VERSION ""

NS_ :

BS_:

BU_: vcu bms inverter

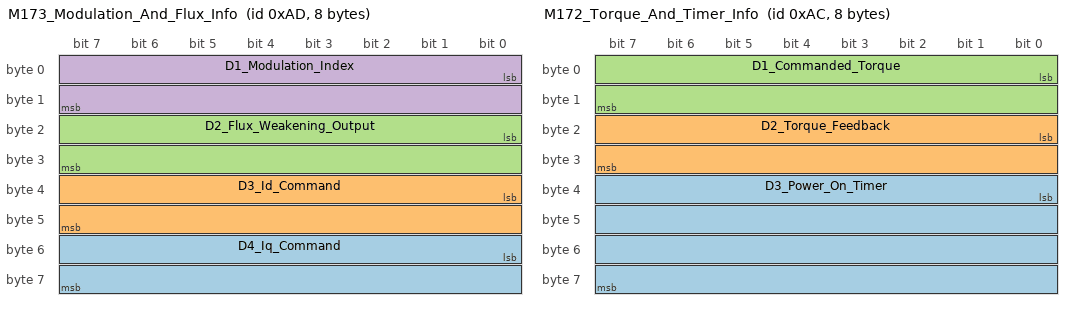
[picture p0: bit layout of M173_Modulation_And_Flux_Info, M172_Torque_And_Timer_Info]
BO_ 173 M173_Modulation_And_Flux_Info: 8 RMS_PM_Controller
 SG_ D4_Iq_Command : 48|16@1- (0.1,0) [-3276.8|3276.7] "" Vector__XXX
 SG_ D3_Id_Command : 32|16@1- (0.1,0) [-3276.8|3276.7] "" Vector__XXX
 SG_ D2_Flux_Weakening_Output : 16|16@1- (0.1,0) [-3276.8|3276.7] "" Vector__XXX
 SG_ D1_Modulation_Index : 0|16@1- (0.0001,0) [-3.2768|3.2767] "" Vector__XXX

BO_ 172 M172_Torque_And_Timer_Info: 8 RMS_PM_Controller
 SG_ D3_Power_On_Timer : 32|32@1+ (0.003,0) [0|12884800.0] "" Vector__XXX
 SG_ D2_Torque_Feedback : 16|16@1- (0.1,0) [-3276.8|3276.7] "" Vector__XXX
 SG_ D1_Commanded_Torque : 0|16@1- (0.1,0) [-3276.8|3276.7] "" Vector__XXX

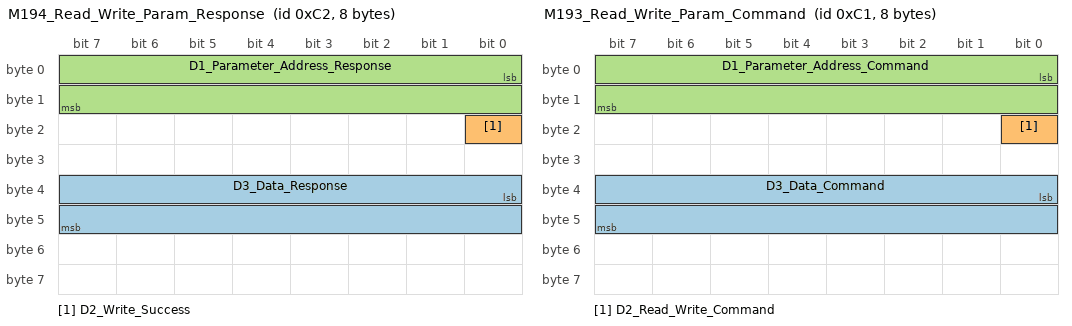
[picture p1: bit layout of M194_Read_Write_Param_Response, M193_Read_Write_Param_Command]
BO_ 194 M194_Read_Write_Param_Response: 8 RMS_PM_Controller
 SG_ D3_Data_Response : 32|16@1- (1,0) [-32768|32767] "" Vector__XXX
 SG_ D2_Write_Success : 16|1@1+ (1,0) [0|1] "" Vector__XXX
 SG_ D1_Parameter_Address_Response : 0|16@1+ (1,0) [0|65535] "" Vector__XXX

BO_ 193 M193_Read_Write_Param_Command: 8 Vector__XXX
 SG_ D3_Data_Command : 32|16@1- (1,0) [-32768|32767] "" Vector__XXX
 SG_ D2_Read_Write_Command : 16|1@1+ (1,0) [0|1] "" Vector__XXX
 SG_ D1_Parameter_Address_Command : 0|16@1+ (1,0) [0|65535] "" Vector__XXX

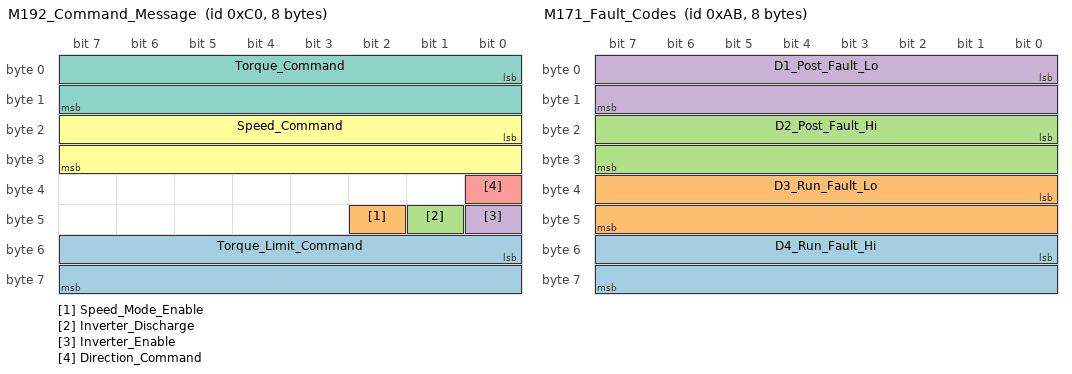
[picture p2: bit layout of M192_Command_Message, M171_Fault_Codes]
BO_ 192 M192_Command_Message: 8 Vector__XXX
 SG_ Torque_Limit_Command : 48|16@1- (0.1,0) [-3276.8|3276.7] "" Vector__XXX
 SG_ Speed_Mode_Enable : 42|1@1+ (1,0) [0|1] "" Vector__XXX
 SG_ Inverter_Discharge : 41|1@1+ (1,0) [0|1] "" Vector__XXX
 SG_ Inverter_Enable : 40|1@1+ (1,0) [0|1] "" Vector__XXX
 SG_ Direction_Command : 32|1@1+ (1,0) [0|1] "" Vector__XXX
 SG_ Speed_Command : 16|16@1- (1,0) [-32768|32767] "" Vector__XXX
 SG_ Torque_Command : 0|16@1- (0.1,0) [-3276.8|3276.7] "" Vector__XXX

BO_ 171 M171_Fault_Codes: 8 RMS_PM_Controller
 SG_ D4_Run_Fault_Hi : 48|16@1+ (1,0) [0|65535] "" Vector__XXX
 SG_ D3_Run_Fault_Lo : 32|16@1+ (1,0) [0|65535] "" Vector__XXX
 SG_ D2_Post_Fault_Hi : 16|16@1+ (1,0) [0|65535] "" Vector__XXX
 SG_ D1_Post_Fault_Lo : 0|16@1+ (1,0) [0|65535] "" Vector__XXX

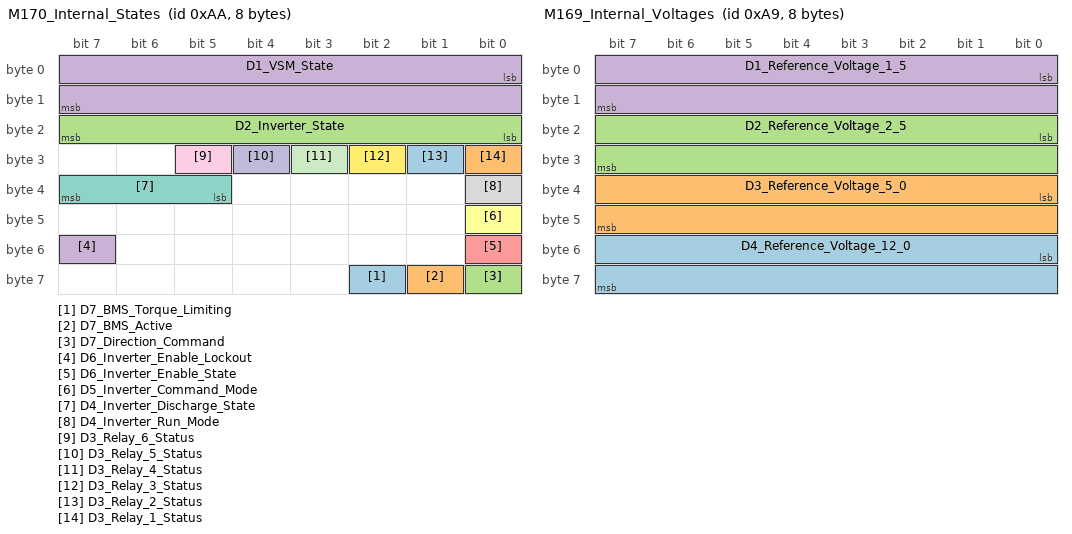
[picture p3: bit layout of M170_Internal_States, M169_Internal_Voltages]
BO_ 170 M170_Internal_States: 8 RMS_PM_Controller
 SG_ D7_BMS_Torque_Limiting : 58|1@1+ (1,0) [0|0] "" Vector__XXX
 SG_ D7_BMS_Active : 57|1@1+ (1,0) [0|1] "" Vector__XXX
 SG_ D7_Direction_Command : 56|1@1+ (1,0) [0|1] "" Vector__XXX
 SG_ D6_Inverter_Enable_Lockout : 55|1@1+ (1,0) [0|1] "" Vector__XXX
 SG_ D6_Inverter_Enable_State : 48|1@1+ (1,0) [0|1] "" Vector__XXX
 SG_ D5_Inverter_Command_Mode : 40|1@1+ (1,0) [0|1] "" Vector__XXX
 SG_ D4_Inverter_Discharge_State : 37|3@1+ (1,0) [0|7] "" Vector__XXX
 SG_ D4_Inverter_Run_Mode : 32|1@1+ (1,0) [0|1] "" Vector__XXX
 SG_ D3_Relay_6_Status : 29|1@1+ (1,0) [0|1] "" Vector__XXX
 SG_ D3_Relay_5_Status : 28|1@1+ (1,0) [0|1] "" Vector__XXX
 SG_ D3_Relay_4_Status : 27|1@1+ (1,0) [0|1] "" Vector__XXX
 SG_ D3_Relay_3_Status : 26|1@1+ (1,0) [0|1] "" Vector__XXX
 SG_ D3_Relay_2_Status : 25|1@1+ (1,0) [0|1] "" Vector__XXX
 SG_ D3_Relay_1_Status : 24|1@1+ (1,0) [0|1] "" Vector__XXX
 SG_ D2_Inverter_State : 16|8@1+ (1,0) [0|255] "" Vector__XXX
 SG_ D1_VSM_State : 0|16@1+ (1,0) [0|15] "" Vector__XXX

BO_ 169 M169_Internal_Voltages: 8 RMS_PM_Controller
 SG_ D4_Reference_Voltage_12_0 : 48|16@1- (0.01,0) [-327.68|327.67] "" Vector__XXX
 SG_ D3_Reference_Voltage_5_0 : 32|16@1- (0.01,0) [-327.68|327.67] "" Vector__XXX
 SG_ D2_Reference_Voltage_2_5 : 16|16@1- (0.01,0) [-327.68|327.67] "" Vector__XXX
 SG_ D1_Reference_Voltage_1_5 : 0|16@1- (0.01,0) [-327.68|327.67] "" Vector__XXX

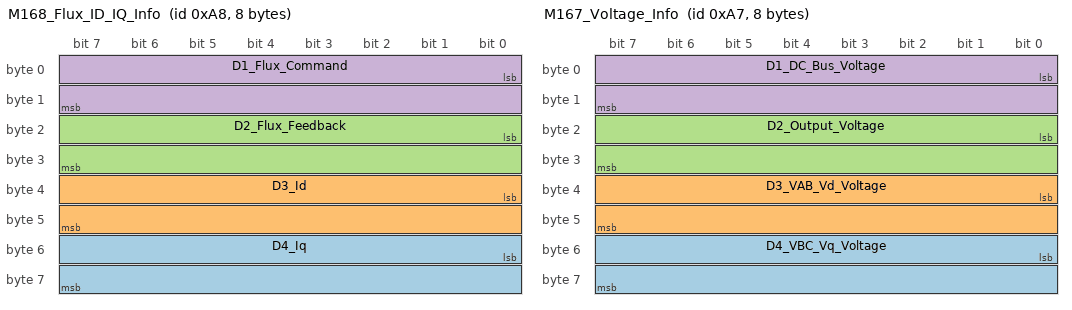
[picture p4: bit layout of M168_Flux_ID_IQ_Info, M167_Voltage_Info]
BO_ 168 M168_Flux_ID_IQ_Info: 8 RMS_PM_Controller
 SG_ D4_Iq : 48|16@1- (0.1,0) [-3276.8|3276.7] "" Vector__XXX
 SG_ D3_Id : 32|16@1- (0.1,0) [-3276.8|3276.7] "" Vector__XXX
 SG_ D2_Flux_Feedback : 16|16@1- (0.001,0) [-32.768|32.767] "" Vector__XXX
 SG_ D1_Flux_Command : 0|16@1- (0.001,0) [-32.768|32.767] "" Vector__XXX

BO_ 167 M167_Voltage_Info: 8 RMS_PM_Controller
 SG_ D4_VBC_Vq_Voltage : 48|16@1- (0.1,0) [-3276.8|3276.7] "" Vector__XXX
 SG_ D3_VAB_Vd_Voltage : 32|16@1- (0.1,0) [-3276.8|3276.7] "" Vector__XXX
 SG_ D2_Output_Voltage : 16|16@1- (0.1,0) [-3276.8|3276.7] "" Vector__XXX
 SG_ D1_DC_Bus_Voltage : 0|16@1- (0.1,0) [-3276.8|3276.7] "" Vector__XXX

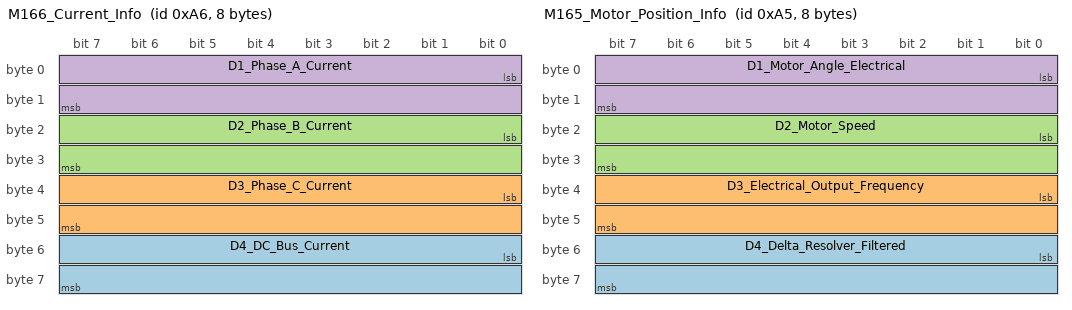
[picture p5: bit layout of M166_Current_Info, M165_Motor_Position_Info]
BO_ 166 M166_Current_Info: 8 RMS_PM_Controller
 SG_ D4_DC_Bus_Current : 48|16@1- (0.1,0) [-3276.8|3276.7] "" Vector__XXX
 SG_ D3_Phase_C_Current : 32|16@1- (0.1,0) [-3276.8|3276.7] "" Vector__XXX
 SG_ D2_Phase_B_Current : 16|16@1- (0.1,0) [-3276.8|3276.7] "" Vector__XXX
 SG_ D1_Phase_A_Current : 0|16@1- (0.1,0) [-3276.8|3276.7] "" Vector__XXX

BO_ 165 M165_Motor_Position_Info: 8 RMS_PM_Controller
 SG_ D4_Delta_Resolver_Filtered : 48|16@1- (0.1,0) [-3276.8|3276.7] "" Vector__XXX
 SG_ D3_Electrical_Output_Frequency : 32|16@1- (0.1,0) [-3276.8|3276.7] "" Vector__XXX
 SG_ D2_Motor_Speed : 16|16@1- (1,0) [-32768|32767] "" Vector__XXX
 SG_ D1_Motor_Angle_Electrical : 0|16@1+ (0.1,0) [0|6553.5] "" Vector__XXX

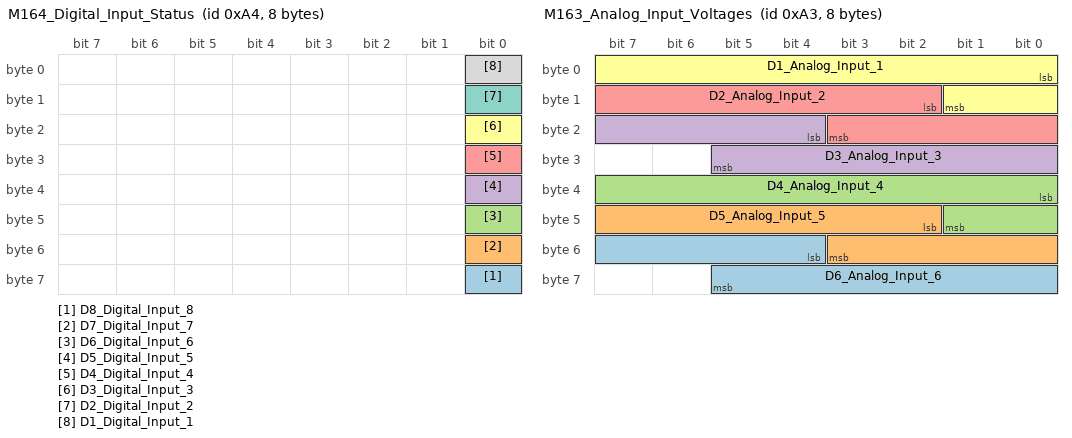
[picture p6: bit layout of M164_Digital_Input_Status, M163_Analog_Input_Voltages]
BO_ 164 M164_Digital_Input_Status: 8 RMS_PM_Controller
 SG_ D8_Digital_Input_8 : 56|1@1+ (1,0) [0|1] "" Vector__XXX
 SG_ D7_Digital_Input_7 : 48|1@1+ (1,0) [0|1] "" Vector__XXX
 SG_ D6_Digital_Input_6 : 40|1@1+ (1,0) [0|1] "" Vector__XXX
 SG_ D5_Digital_Input_5 : 32|1@1+ (1,0) [0|1] "" Vector__XXX
 SG_ D4_Digital_Input_4 : 24|1@1+ (1,0) [0|1] "" Vector__XXX
 SG_ D3_Digital_Input_3 : 16|1@1+ (1,0) [0|1] "" Vector__XXX
 SG_ D2_Digital_Input_2 : 8|1@1+ (1,0) [0|1] "" Vector__XXX
 SG_ D1_Digital_Input_1 : 0|1@1+ (1,0) [0|1] "" Vector__XXX

BO_ 163 M163_Analog_Input_Voltages: 8 RMS_PM_Controller
 SG_ D6_Analog_Input_6 : 52|10@1+ (0.01,0) [0|10.23] "" Vector__XXX
 SG_ D5_Analog_Input_5 : 42|10@1+ (0.01,0) [0|10.23] "" Vector__XXX
 SG_ D4_Analog_Input_4 : 32|10@1+ (0.01,0) [0|10.23] "" Vector__XXX
 SG_ D3_Analog_Input_3 : 20|10@1+ (0.01,0) [0|10.23] "" Vector__XXX
 SG_ D2_Analog_Input_2 : 10|10@1+ (0.01,0) [0|10.23] "" Vector__XXX
 SG_ D1_Analog_Input_1 : 0|10@1+ (0.01,0) [0|10.23] "" Vector__XXX

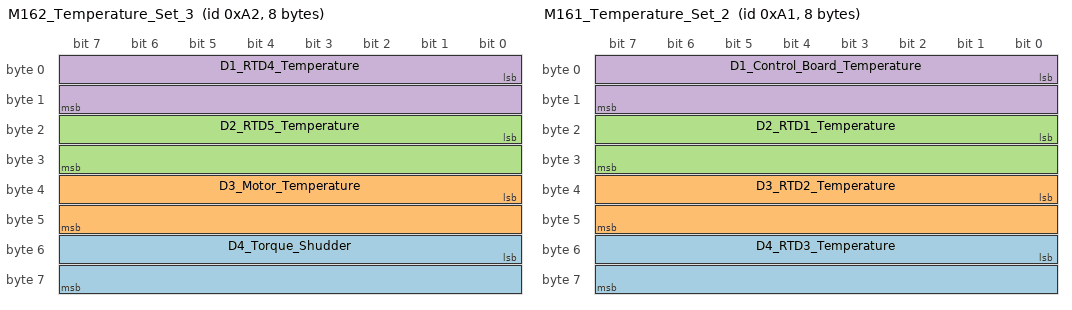
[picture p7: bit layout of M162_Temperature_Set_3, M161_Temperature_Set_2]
BO_ 162 M162_Temperature_Set_3: 8 RMS_PM_Controller
 SG_ D4_Torque_Shudder : 48|16@1- (0.1,0) [-3276.8|3276.7] "" Vector__XXX
 SG_ D3_Motor_Temperature : 32|16@1- (0.1,0) [-3276.8|3276.7] "" Vector__XXX
 SG_ D2_RTD5_Temperature : 16|16@1- (0.1,0) [-3276.8|3276.7] "" Vector__XXX
 SG_ D1_RTD4_Temperature : 0|16@1- (0.1,0) [-3276.8|3276.7] "" Vector__XXX

BO_ 161 M161_Temperature_Set_2: 8 RMS_PM_Controller
 SG_ D4_RTD3_Temperature : 48|16@1- (0.1,0) [-3276.8|3276.7] "" Vector__XXX
 SG_ D3_RTD2_Temperature : 32|16@1- (0.1,0) [-3276.8|3276.7] "" Vector__XXX
 SG_ D2_RTD1_Temperature : 16|16@1- (0.1,0) [-3276.8|3276.7] "" Vector__XXX
 SG_ D1_Control_Board_Temperature : 0|16@1- (0.1,0) [-3276.8|3276.7] "" Vector__XXX

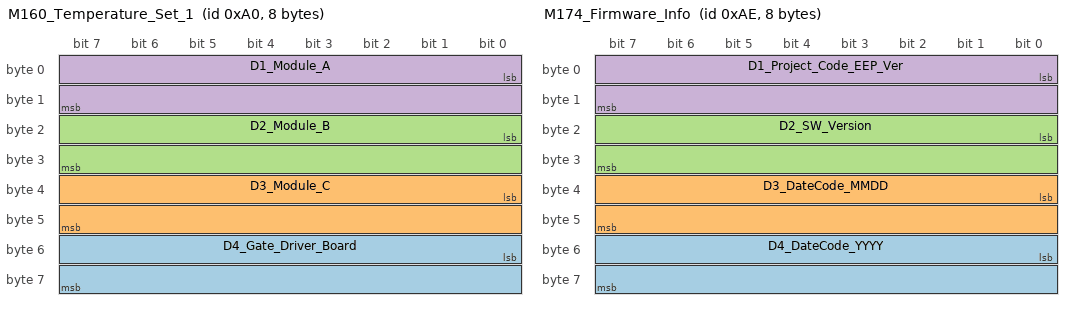
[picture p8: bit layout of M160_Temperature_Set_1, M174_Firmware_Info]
BO_ 160 M160_Temperature_Set_1: 8 RMS_PM_Controller
 SG_ D4_Gate_Driver_Board : 48|16@1- (0.1,0) [-3276.8|3276.7] "" Vector__XXX
 SG_ D3_Module_C : 32|16@1- (0.1,0) [-3276.8|3276.7] "" Vector__XXX
 SG_ D2_Module_B : 16|16@1- (0.1,0) [-3276.8|3276.7] "" Vector__XXX
 SG_ D1_Module_A : 0|16@1- (0.1,0) [-3276.8|3276.7] "" Vector__XXX

BO_ 174 M174_Firmware_Info: 8 RMS_PM_Controller
 SG_ D4_DateCode_YYYY : 48|16@1+ (1,0) [0|65535] "" Vector__XXX
 SG_ D3_DateCode_MMDD : 32|16@1+ (1,0) [0|65535] "" Vector__XXX
 SG_ D2_SW_Version : 16|16@1+ (1,0) [0|65535] "" Vector__XXX
 SG_ D1_Project_Code_EEP_Ver : 0|16@1+ (1,0) [0|65535] "" Vector__XXX

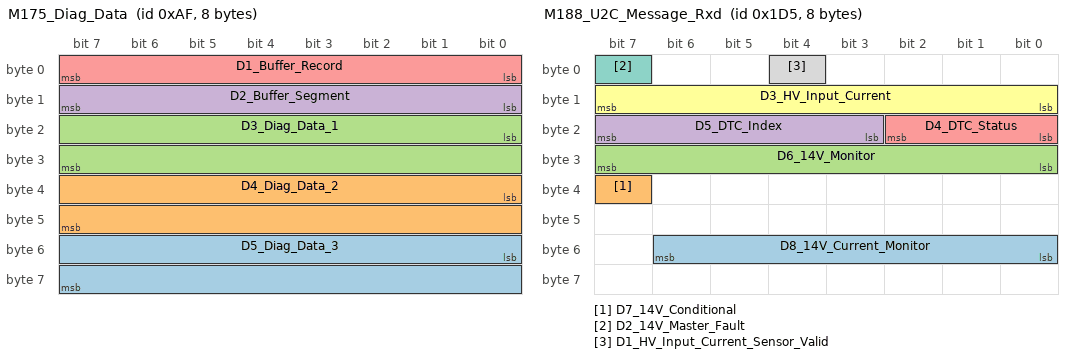
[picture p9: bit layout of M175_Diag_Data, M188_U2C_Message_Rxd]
BO_ 175 M175_Diag_Data: 8 RMS_PM_Controller
 SG_ D5_Diag_Data_3 : 48|16@1- (1,0) [-32768|32767] "" Vector__XXX
 SG_ D4_Diag_Data_2 : 32|16@1- (1,0) [-32768|32767] "" Vector__XXX
 SG_ D3_Diag_Data_1 : 16|16@1- (1,0) [-32768|32767] "" Vector__XXX
 SG_ D2_Buffer_Segment : 8|8@1+ (1,0) [0|5] "" Vector__XXX
 SG_ D1_Buffer_Record : 0|8@1+ (1,0) [0|255] "" Vector__XXX

BO_ 471 M187_U2C_Command_Txd: 8 RMS_PM_Controller
 SG_ D2_Setpoint_Calc : 8|8@1+ (1,0) [0|255] "" Vector__XXX
 SG_ D1_ID_Byte : 0|8@1+ (1,0) [0|255] "" Vector__XXX

BO_ 469 M188_U2C_Message_Rxd: 8 Vector__XXX
 SG_ D8_14V_Current_Monitor : 48|7@1+ (1,0) [0|127] "" Vector__XXX
 SG_ D7_14V_Conditional : 39|1@1+ (1,0) [0|1] "" Vector__XXX
 SG_ D6_14V_Monitor : 24|8@1+ (1,0) [0|255] "" Vector__XXX
 SG_ D5_DTC_Index : 19|5@1+ (1,0) [0|31] "" Vector__XXX
 SG_ D4_DTC_Status : 16|3@1+ (1,0) [0|7] "" Vector__XXX
 SG_ D3_HV_Input_Current : 8|8@1+ (1,0) [0|255] "" Vector__XXX
 SG_ D2_14V_Master_Fault : 7|1@1+ (1,0) [0|1] "" Vector__XXX
 SG_ D1_HV_Input_Current_Sensor_Valid : 4|1@1+ (1,0) [0|1] "" Vector__XXX

BO_ 514 BMS_Current_Limit: 8 Vector__XXX
 SG_ D2_Max_Charge_Current : 16|16@1+ (1,0) [0|1000] "" Vector__XXX
 SG_ D1_Max_Discharge_Current : 0|16@1+ (1,0) [0|1000] "" Vector__XXX

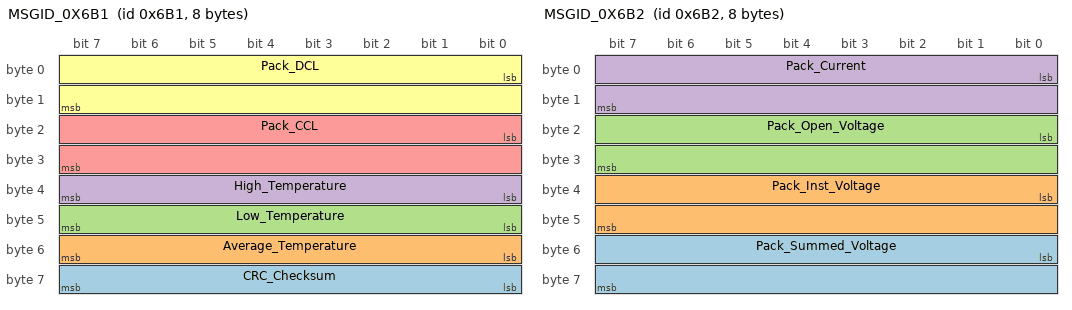
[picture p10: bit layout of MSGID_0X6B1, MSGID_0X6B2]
BO_ 1713 MSGID_0X6B1: 8 BMS
 SG_ CRC_Checksum : 63|8@0+ (1,0) [0|0] "" Vector__XXX
 SG_ Average_Temperature : 55|8@0+ (1,0) [0|0] "" Vector__XXX
 SG_ Low_Temperature : 47|8@0+ (1,0) [0|0] "" Vector__XXX
 SG_ High_Temperature : 39|8@0+ (1,0) [0|0] "" Vector__XXX
 SG_ Pack_CCL : 16|16@1+ (1,0) [0|0] "" Vector__XXX
 SG_ Pack_DCL : 0|16@1+ (1,0) [0|0] "" Vector__XXX

BO_ 1714 MSGID_0X6B2: 8 BMS
 SG_ Pack_Summed_Voltage : 48|16@1+ (0.01,0) [0|0] "" Vector__XXX
 SG_ Pack_Inst_Voltage : 32|16@1+ (0.1,0) [0|0] "" Vector__XXX
 SG_ Pack_Open_Voltage : 16|16@1+ (0.1,0) [0|0] "" Vector__XXX
 SG_ Pack_Current : 0|16@1- (0.1,0) [0|0] "" Vector__XXX

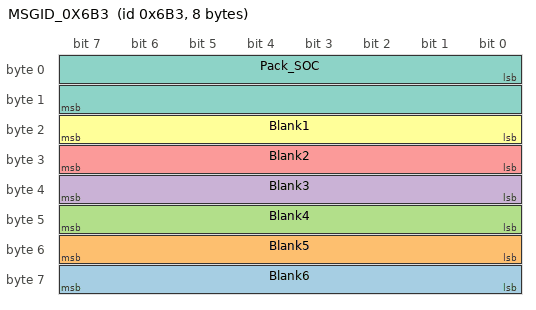
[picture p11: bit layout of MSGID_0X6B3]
BO_ 1715 MSGID_0X6B3: 8 BMS
 SG_ Blank6 : 63|8@0+ (1,0) [0|0] "" Vector__XXX
 SG_ Blank5 : 55|8@0+ (1,0) [0|0] "" Vector__XXX
 SG_ Blank4 : 47|8@0+ (1,0) [0|0] "" Vector__XXX
 SG_ Blank3 : 39|8@0+ (1,0) [0|0] "" Vector__XXX
 SG_ Blank2 : 31|8@0+ (1,0) [0|0] "" Vector__XXX
 SG_ Blank1 : 23|8@0+ (1,0) [0|0] "" Vector__XXX
 SG_ Pack_SOC : 0|16@1+ (0.5,0) [0|0] "" Vector__XXX

CM_ BU_ vcu "the vehicle control unit";
CM_ BO_ 194 "To write a parameter use message 0x0C1 with byte #2 set to 1 (write). 
To read a parameter use message 0x0C1 with byte #2 to set 0 (read). ";
CM_ BO_ 193 "To write a parameter use message 0x0C1 with byte #2 set to 1 (write). 
To read a parameter use message 0x0C1 with byte #2 to set 0 (read). ";
CM_ BO_ 192 "The command message is used to transmit data to the controller. This message is sent from a user supplied external controller to the PMxxx controller.";
CM_ BO_ 514 "Sent by BMS";
CM_ BO_ 1713 "This ID Transmits at 104 ms.";
CM_ BO_ 1714 "This ID Transmits at 48 ms.";
CM_ BO_ 1715 "This ID Transmits at 1008 ms.";
BA_DEF_ SG_  "SystemSignalLongSymbol" STRING ;
BA_DEF_DEF_  "SystemSignalLongSymbol" "";
BA_ "SystemSignalLongSymbol" SG_ 469 D1_HV_Input_Current_Sensor_Valid "D1_HV_Input_Current_Sensor_Validity";
VAL_ 192 Inverter_Discharge 0 "Discharge Disable" 1 "Discharge Enable (if EEPROM parameter is set)" ;
VAL_ 192 Inverter_Enable 0 "Turn the inverter OFF" 1 "Turn the Inverter ON" ;
VAL_ 192 Direction_Command 0 "CW" 1 "CCW" ;
VAL_ 170 D2_Inverter_State 0 "Power up" 1 "Stop" 2 "Open Loop" 3 "Closed Loop" 4 "Internal State" 5 "Internal State" 6 "Internal State" 7 "Internal State" 8 "Idle Run" 9 "Idle Stop" 10 "Internal State" 11 "Intern State" 12 "Internal State" ;
VAL_ 170 D1_VSM_State 0 "VSM Start State" 1 "Pre-Charge Init state" 2 "pre-charge active state" 3 "pre-charge complete state" 4 "VSM wait state" 5 "VSM ready state" 6 "Motor Running State" 7 "blink fault code state" 14 "Shutdown state for Key Switch Mode 1" 15 "Reset the inverter" ;
